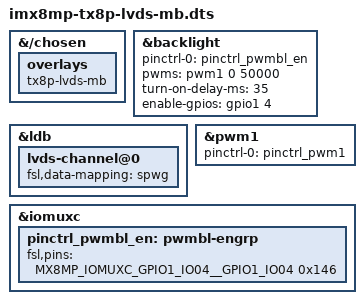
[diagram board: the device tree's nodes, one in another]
// SPDX-License-Identifier: (GPL-2.0 OR MIT)
/*
 * Copyright 2022 Lothar Waßmann <LW@KARO-electronics.de>
 *
 */

/dts-v1/;

/plugin/;

#include <dt-bindings/gpio/gpio.h>
#include "imx8mp-pinfunc.h"

&{/chosen} {
	overlays {
		tx8p-lvds-mb;
	};
};

&backlight {
	pinctrl-names = "default";
	pinctrl-0 = <&pinctrl_pwmbl_en>;
	pwms = <&pwm1 0 50000>;
	turn-on-delay-ms = <35>;
	enable-gpios = <&gpio1 4 GPIO_ACTIVE_HIGH>;
};

&ldb {
	lvds-channel@0 {
		fsl,data-mapping = "spwg";
	};
};

&pwm1 {
	pinctrl-names = "default";
	pinctrl-0 = <&pinctrl_pwm1>;
};

&iomuxc {
	pinctrl_pwmbl_en: pwmbl-engrp {
		fsl,pins = <
			MX8MP_IOMUXC_GPIO1_IO04__GPIO1_IO04		0x146
		>;
	};
};
